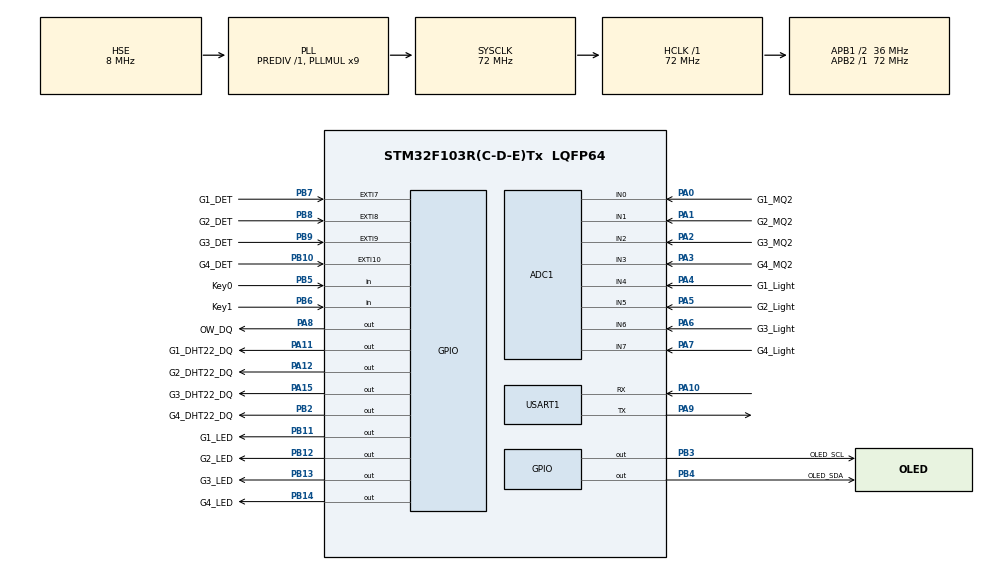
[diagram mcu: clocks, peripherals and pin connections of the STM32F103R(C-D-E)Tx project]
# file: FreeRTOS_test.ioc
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ADC1.Channel-10\#ChannelRegularConversion=ADC_CHANNEL_7
ADC1.Channel-3\#ChannelRegularConversion=ADC_CHANNEL_0
ADC1.Channel-4\#ChannelRegularConversion=ADC_CHANNEL_1
ADC1.Channel-5\#ChannelRegularConversion=ADC_CHANNEL_2
ADC1.Channel-6\#ChannelRegularConversion=ADC_CHANNEL_3
ADC1.Channel-7\#ChannelRegularConversion=ADC_CHANNEL_4
ADC1.Channel-8\#ChannelRegularConversion=ADC_CHANNEL_5
ADC1.Channel-9\#ChannelRegularConversion=ADC_CHANNEL_6
ADC1.ContinuousConvMode=ENABLE
ADC1.NbrOfConversion=8
ADC1.NbrOfConversionFlag=1
ADC1.Rank-10\#ChannelRegularConversion=8
ADC1.Rank-3\#ChannelRegularConversion=1
ADC1.Rank-4\#ChannelRegularConversion=2
ADC1.Rank-5\#ChannelRegularConversion=3
ADC1.Rank-6\#ChannelRegularConversion=4
ADC1.Rank-7\#ChannelRegularConversion=5
ADC1.Rank-8\#ChannelRegularConversion=6
ADC1.Rank-9\#ChannelRegularConversion=7
ADC1.SamplingTime-10\#ChannelRegularConversion=ADC_SAMPLETIME_55CYCLES_5
ADC1.SamplingTime-3\#ChannelRegularConversion=ADC_SAMPLETIME_55CYCLES_5
ADC1.SamplingTime-4\#ChannelRegularConversion=ADC_SAMPLETIME_55CYCLES_5
ADC1.SamplingTime-5\#ChannelRegularConversion=ADC_SAMPLETIME_55CYCLES_5
ADC1.SamplingTime-6\#ChannelRegularConversion=ADC_SAMPLETIME_55CYCLES_5
ADC1.SamplingTime-7\#ChannelRegularConversion=ADC_SAMPLETIME_55CYCLES_5
ADC1.SamplingTime-8\#ChannelRegularConversion=ADC_SAMPLETIME_55CYCLES_5
ADC1.SamplingTime-9\#ChannelRegularConversion=ADC_SAMPLETIME_55CYCLES_5
ADC1.master=1
Dma.ADC1.0.Direction=DMA_PERIPH_TO_MEMORY
Dma.ADC1.0.Instance=DMA1_Channel1
Dma.ADC1.0.MemDataAlignment=DMA_MDATAALIGN_HALFWORD
Dma.ADC1.0.MemInc=DMA_MINC_ENABLE
Dma.ADC1.0.Mode=DMA_CIRCULAR
Dma.ADC1.0.PeriphDataAlignment=DMA_PDATAALIGN_HALFWORD
Dma.ADC1.0.PeriphInc=DMA_PINC_DISABLE
Dma.ADC1.0.Priority=DMA_PRIORITY_LOW
Dma.Request0=ADC1
Mcu.Family=STM32F1
Mcu.Name=STM32F103R(C-D-E)Tx
Mcu.Package=LQFP64
NVIC.DMA1_Channel1_IRQn=true\:0\:0\:false\:false\:true\:false\:true\:true
NVIC.EXTI9_5_IRQn=true\:4\:0\:true\:false\:true\:true\:true\:true
NVIC.PriorityGroup=NVIC_PRIORITYGROUP_4
NVIC.TIM4_IRQn=true\:15\:0\:true\:false\:true\:false\:true\:true
NVIC.TimeBase=TIM4_IRQn
NVIC.TimeBaseIP=TIM4
PA0-WKUP.GPIO_Label=G1_MQ2 
PA0-WKUP.Signal=ADCx_IN0
PA1.GPIO_Label=G2_MQ2 
PA1.Signal=ADCx_IN1
PA10.Mode=Asynchronous
PA10.Signal=USART1_RX
PA11.GPIO_Label=G1_DHT22_DQ 
PA11.GPIO_ModeDefaultOutputPP=GPIO_MODE_OUTPUT_OD
PA11.GPIO_PuPd=GPIO_PULLUP
PA11.Signal=GPIO_Output
PA12.GPIO_Label=G2_DHT22_DQ 
PA12.GPIO_ModeDefaultOutputPP=GPIO_MODE_OUTPUT_OD
PA12.GPIO_PuPd=GPIO_PULLUP
PA12.Signal=GPIO_Output
PA13.Mode=Serial_Wire
PA13.Signal=SYS_JTMS-SWDIO
PA14.Mode=Serial_Wire
PA14.Signal=SYS_JTCK-SWCLK
PA15.GPIO_Label=G3_DHT22_DQ 
PA15.GPIO_ModeDefaultOutputPP=GPIO_MODE_OUTPUT_OD
PA15.GPIO_PuPd=GPIO_PULLUP
PA15.Signal=GPIO_Output
PA2.GPIO_Label=G3_MQ2 
PA2.Signal=ADCx_IN2
PA3.GPIO_Label=G4_MQ2 
PA3.Signal=ADCx_IN3
PA4.GPIO_Label=G1_Light 
PA4.Signal=ADCx_IN4
PA5.GPIO_Label=G2_Light 
PA5.Signal=ADCx_IN5
PA6.GPIO_Label=G3_Light 
PA6.Signal=ADCx_IN6
PA7.GPIO_Label=G4_Light 
PA7.Signal=ADCx_IN7
PA8.GPIO_Label=OW_DQ 
PA8.GPIO_ModeDefaultOutputPP=GPIO_MODE_OUTPUT_OD
PA8.GPIO_PuPd=GPIO_PULLUP
PA8.Signal=GPIO_Output
PA9.Mode=Asynchronous
PA9.Signal=USART1_TX
PB10.GPIO_Label=G4_DET
PB10.GPIO_ModeDefaultEXTI=GPIO_MODE_IT_RISING_FALLING
PB10.GPIO_PuPd=GPIO_PULLUP
PB10.Signal=GPXTI10
PB11.GPIO_Label=G1_LED
PB11.Signal=GPIO_Output
PB12.GPIO_Label=G2_LED
PB12.Signal=GPIO_Output
PB13.GPIO_Label=G3_LED
PB13.Signal=GPIO_Output
PB14.GPIO_Label=G4_LED
PB14.Signal=GPIO_Output
PB2.GPIO_Label=G4_DHT22_DQ 
PB2.GPIO_ModeDefaultOutputPP=GPIO_MODE_OUTPUT_OD
PB2.GPIO_PuPd=GPIO_PULLUP
PB2.Signal=GPIO_Output
PB3.GPIO_Label=OLED_SCL 
PB3.GPIO_ModeDefaultOutputPP=GPIO_MODE_OUTPUT_OD
PB3.GPIO_PuPd=GPIO_PULLUP
PB3.Signal=GPIO_Output
PB4.GPIO_Label=OLED_SDA 
PB4.GPIO_ModeDefaultOutputPP=GPIO_MODE_OUTPUT_OD
PB4.GPIO_PuPd=GPIO_PULLUP
PB4.Signal=GPIO_Output
PB5.GPIO_Label=Key0
PB5.GPIO_PuPd=GPIO_PULLUP
PB5.Signal=GPIO_Input
PB6.GPIO_Label=Key1
PB6.GPIO_PuPd=GPIO_PULLUP
PB6.Signal=GPIO_Input
PB7.GPIO_Label=G1_DET
PB7.GPIO_ModeDefaultEXTI=GPIO_MODE_IT_RISING_FALLING
PB7.GPIO_PuPd=GPIO_PULLUP
PB7.Signal=GPXTI7
PB8.GPIO_Label=G2_DET
PB8.GPIO_ModeDefaultEXTI=GPIO_MODE_IT_RISING_FALLING
PB8.GPIO_PuPd=GPIO_PULLUP
PB8.Signal=GPXTI8
PB9.GPIO_Label=G3_DET
PB9.GPIO_ModeDefaultEXTI=GPIO_MODE_IT_RISING_FALLING
PB9.GPIO_PuPd=GPIO_PULLUP
PB9.Signal=GPXTI9
PD0-OSC_IN.Mode=HSE-External-Oscillator
PD0-OSC_IN.Signal=RCC_OSC_IN
PD1-OSC_OUT.Mode=HSE-External-Oscillator
PD1-OSC_OUT.Signal=RCC_OSC_OUT
ProjectManager.HeapSize=0x200
ProjectManager.StackSize=0x400
ProjectManager.TargetToolchain=CMake
RCC.ADCPresc=RCC_ADCPCLK2_DIV6
RCC.AHBFreq_Value=72000000
RCC.APB1CLKDivider=RCC_HCLK_DIV2
RCC.APB1Freq_Value=36000000
RCC.APB1TimFreq_Value=72000000
RCC.APB2Freq_Value=72000000
RCC.APB2TimFreq_Value=72000000
RCC.HCLKFreq_Value=72000000
RCC.PLLMUL=RCC_PLL_MUL9
RCC.PLLSourceVirtual=RCC_PLLSOURCE_HSE
RCC.SYSCLKFreq_VALUE=72000000
RCC.SYSCLKSource=RCC_SYSCLKSOURCE_PLLCLK
RCC.USBFreq_Value=72000000
SH.ADCx_IN0.0=ADC1_IN0,IN0
SH.ADCx_IN1.0=ADC1_IN1,IN1
SH.ADCx_IN2.0=ADC1_IN2,IN2
SH.ADCx_IN3.0=ADC1_IN3,IN3
SH.ADCx_IN4.0=ADC1_IN4,IN4
SH.ADCx_IN5.0=ADC1_IN5,IN5
SH.ADCx_IN6.0=ADC1_IN6,IN6
SH.ADCx_IN7.0=ADC1_IN7,IN7
USART1.VirtualMode=VM_ASYNC
VP_SYS_VS_tim4.Mode=TIM4
board=custom

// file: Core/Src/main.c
/* USER CODE BEGIN Header */
/**
  ******************************************************************************
  * @file           : main.c
  * @brief          : Main program body
  ******************************************************************************
  * @attention
  *
  * Copyright (c) 2026 STMicroelectronics.
  * All rights reserved.
  *
  * This software is licensed under terms that can be found in the LICENSE file
  * in the root directory of this software component.
  * If no LICENSE file comes with this software, it is provided AS-IS.
  *
  ******************************************************************************
  */
/* USER CODE END Header */
#include "main.h"
#include "adc.h"
#include "dma.h"
#include "usart.h"
#include "gpio.h"

/* USER CODE BEGIN Includes */
#include "start_task.h"
#include "FreeRTOS.h"
#include "task.h"

/* USER CODE END Includes */

void SystemClock_Config(void);

int main(void)
{

  /* MCU Configuration--------------------------------------------------------*/

  /* Reset of all peripherals, Initializes the Flash interface and the Systick. */
  HAL_Init();

  /* Configure the system clock */
  SystemClock_Config();

  /* Initialize all configured peripherals */
  MX_GPIO_Init();
  MX_DMA_Init();
  MX_ADC1_Init();
  MX_USART1_UART_Init();
  /* USER CODE BEGIN 2 */
  HAL_NVIC_DisableIRQ(DMA1_Channel1_IRQn);
  xTaskCreate(StartTask, START_TASK_NAME, START_TASK_STACK_SIZE, NULL, START_TASK_PRIORITY, &StartTaskHandle);
  vTaskStartScheduler();

  /* USER CODE END 2 */

  /* Infinite loop */
  while (1)
  {

  }
}

void SystemClock_Config(void)
{
  RCC_OscInitTypeDef RCC_OscInitStruct = {0};
  RCC_ClkInitTypeDef RCC_ClkInitStruct = {0};
  RCC_PeriphCLKInitTypeDef PeriphClkInit = {0};

  /** Initializes the RCC Oscillators according to the specified parameters
  * in the RCC_OscInitTypeDef structure.
  */
  RCC_OscInitStruct.OscillatorType = RCC_OSCILLATORTYPE_HSE;
  RCC_OscInitStruct.HSEState = RCC_HSE_ON;
  RCC_OscInitStruct.HSEPredivValue = RCC_HSE_PREDIV_DIV1;
  RCC_OscInitStruct.HSIState = RCC_HSI_ON;
  RCC_OscInitStruct.PLL.PLLState = RCC_PLL_ON;
  RCC_OscInitStruct.PLL.PLLSource = RCC_PLLSOURCE_HSE;
  RCC_OscInitStruct.PLL.PLLMUL = RCC_PLL_MUL9;
  if (HAL_RCC_OscConfig(&RCC_OscInitStruct) != HAL_OK)
  {
    Error_Handler();
  }

  /** Initializes the CPU, AHB and APB buses clocks
  */
  RCC_ClkInitStruct.ClockType = RCC_CLOCKTYPE_HCLK|RCC_CLOCKTYPE_SYSCLK
                              |RCC_CLOCKTYPE_PCLK1|RCC_CLOCKTYPE_PCLK2;
  RCC_ClkInitStruct.SYSCLKSource = RCC_SYSCLKSOURCE_PLLCLK;
  RCC_ClkInitStruct.AHBCLKDivider = RCC_SYSCLK_DIV1;
  RCC_ClkInitStruct.APB1CLKDivider = RCC_HCLK_DIV2;
  RCC_ClkInitStruct.APB2CLKDivider = RCC_HCLK_DIV1;

  if (HAL_RCC_ClockConfig(&RCC_ClkInitStruct, FLASH_LATENCY_2) != HAL_OK)
  {
    Error_Handler();
  }
  PeriphClkInit.PeriphClockSelection = RCC_PERIPHCLK_ADC;
  PeriphClkInit.AdcClockSelection = RCC_ADCPCLK2_DIV6;
  if (HAL_RCCEx_PeriphCLKConfig(&PeriphClkInit) != HAL_OK)
  {
    Error_Handler();
  }
}

/* USER CODE BEGIN 4 */

/**
  * @brief  FreeRTOS任务栈溢出钩子函数
  * @param  xTask: 发生栈溢出的任务句柄
  * @param  pcTaskName: 发生栈溢出的任务名称
  * @note   一旦进入该钩子，系统会关闭中断并停在死循环中等待排查
  * @retval 无
  */
void vApplicationStackOverflowHook(TaskHandle_t xTask, char *pcTaskName)
{
  (void)xTask;
  (void)pcTaskName;

  taskDISABLE_INTERRUPTS();
  while (1)
  {
  }
}

/**
  * @brief  FreeRTOS内存分配失败钩子函数
  * @param  无
  * @note   当动态内存申请失败时进入该函数，系统会关闭中断并停机
  * @retval 无
  */
void vApplicationMallocFailedHook(void)
{
  taskDISABLE_INTERRUPTS();
  while (1)
  {
  }
}

/* USER CODE END 4 */

void HAL_TIM_PeriodElapsedCallback(TIM_HandleTypeDef *htim)
{
  if (htim->Instance == TIM4)
  {
    HAL_IncTick();
  }
}

void Error_Handler(void)
{
  __disable_irq();
  while (1)
  {
  }
}
